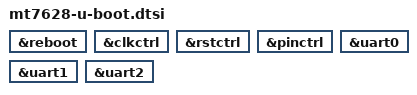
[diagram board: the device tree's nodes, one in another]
// SPDX-License-Identifier: GPL-2.0
/*
 * Copyright (C) 2020 MediaTek Inc.
 *
 * Author: Weijie Gao <weijie.gao@mediatek.com>
 */

&reboot {
	bootph-all;
};

&clkctrl {
	bootph-all;
};

&rstctrl {
	bootph-all;
};

&pinctrl {
	bootph-all;
};

&uart0 {
	bootph-all;
};

#ifndef CONFIG_BOARD_MT7628_GENERIC
&uart1 {
	bootph-all;
};

&uart2 {
	bootph-all;
};
#endif
